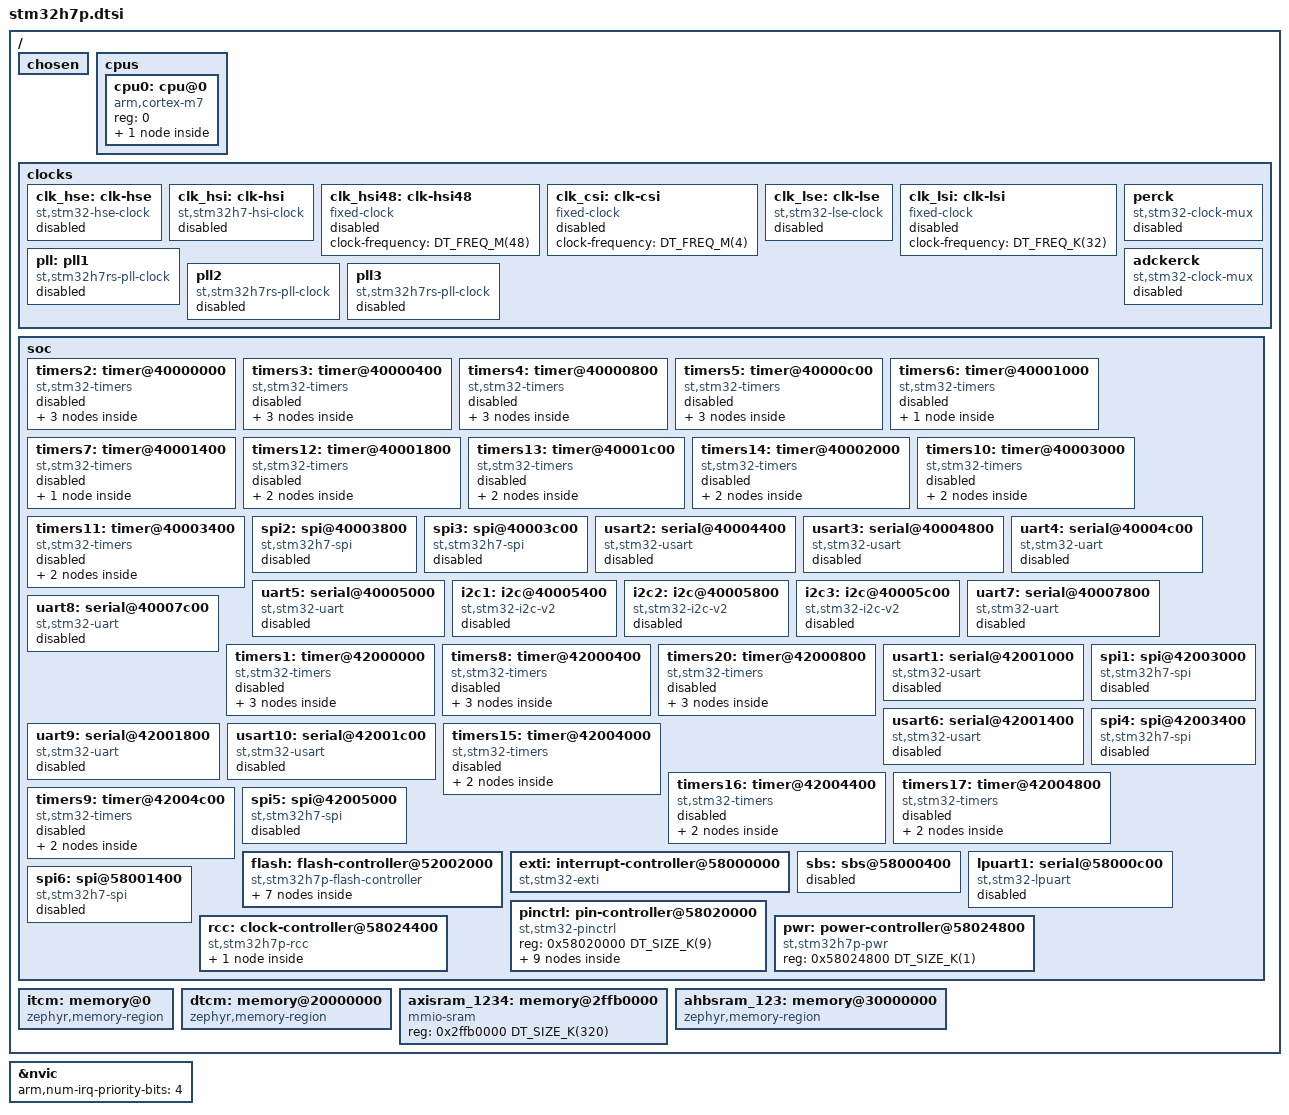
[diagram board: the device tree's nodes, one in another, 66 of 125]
/*
 * SPDX-FileCopyrightText: Copyright (c) 2026 STMicroelectronics
 *
 * SPDX-License-Identifier: Apache-2.0
 */

#include <arm/armv7-m.dtsi>
#include <zephyr/dt-bindings/adc/adc.h>
#include <zephyr/dt-bindings/clock/stm32h7p_clock.h>
#include <zephyr/dt-bindings/gpio/gpio.h>
#include <zephyr/dt-bindings/i2c/i2c.h>
#include <zephyr/dt-bindings/reset/stm32h7p_reset.h>
#include <zephyr/dt-bindings/dma/stm32_dma.h>
#include <zephyr/dt-bindings/power/stm32_pwr.h>
#include <zephyr/dt-bindings/pwm/pwm.h>
#include <zephyr/dt-bindings/sensor/qdec_stm32.h>
#include <freq.h>
#include <mem.h>

/ {
	chosen {
		zephyr,flash-controller = &flash;
		zephyr,flash = &flash0;
		zephyr,sram = &axisram_1234;
	};

	cpus {
		#address-cells = <1>;
		#size-cells = <0>;

		cpu0: cpu@0 {
			compatible = "arm,cortex-m7";
			reg = <0>;
			device_type = "cpu";
			#address-cells = <1>;
			#size-cells = <1>;

			mpu: mpu@e000ed90 {
				compatible = "arm,armv7m-mpu";
				reg = <0xe000ed90 0x40>;
			};
		};
	};

	clocks {
		clk_hse: clk-hse {
			compatible = "st,stm32-hse-clock";
			#clock-cells = <0>;
			status = "disabled";
		};

		clk_hsi: clk-hsi {
			compatible = "st,stm32h7-hsi-clock";
			#clock-cells = <0>;
			hsi-div = <1>;
			clock-frequency = <DT_FREQ_M(64)>;
			status = "disabled";
		};

		clk_hsi48: clk-hsi48 {
			compatible = "fixed-clock";
			#clock-cells = <0>;
			clock-frequency = <DT_FREQ_M(48)>;
			status = "disabled";
		};

		clk_csi: clk-csi {
			compatible = "fixed-clock";
			#clock-cells = <0>;
			clock-frequency = <DT_FREQ_M(4)>;
			status = "disabled";
		};

		clk_lse: clk-lse {
			compatible = "st,stm32-lse-clock";
			#clock-cells = <0>;
			clock-frequency = <32768>;
			driving-capability = <0>;
			status = "disabled";
		};

		clk_lsi: clk-lsi {
			compatible = "fixed-clock";
			#clock-cells = <0>;
			clock-frequency = <DT_FREQ_K(32)>;
			status = "disabled";
		};

		/* NOTE: PLL1 does not have R and T outputs */
		pll: pll1 {
			compatible = "st,stm32h7rs-pll-clock";
			#clock-cells = <0>;
			status = "disabled";
		};

		pll2: pll2 {
			compatible = "st,stm32h7rs-pll-clock";
			#clock-cells = <0>;
			status = "disabled";
		};

		/* NOTE: PLL3 does not have T output */
		pll3: pll3 {
			compatible = "st,stm32h7rs-pll-clock";
			#clock-cells = <0>;
			status = "disabled";
		};

		perck: perck {
			compatible = "st,stm32-clock-mux";
			#clock-cells = <0>;
			status = "disabled";
		};

		adckerck: adckerck {
			compatible = "st,stm32-clock-mux";
			#clock-cells = <0>;
			status = "disabled";
		};
	};

	soc {
		/* APB1 peripherals */
		timers2: timer@40000000 {
			compatible = "st,stm32-timers";
			reg = <0x40000000 DT_SIZE_K(1)>;
			clocks = <&rcc STM32_CLOCK(APB1, 0)>,
				 <&rcc STM32_SRC_TIMCK NO_SEL>;
			resets = <&rctl STM32_RESET(APB1L, 0)>;
			interrupts = <51 0>;
			interrupt-names = "global";
			st,prescaler = <0>;
			status = "disabled";

			counter {
				compatible = "st,stm32-counter";
				status = "disabled";
			};

			pwm {
				compatible = "st,stm32-pwm";
				#pwm-cells = <3>;
				status = "disabled";
			};

			qdec {
				compatible = "st,stm32-qdec";
				st,input-filter-level = <NO_FILTER>;
				status = "disabled";
			};
		};

		timers3: timer@40000400 {
			compatible = "st,stm32-timers";
			reg = <0x40000400 DT_SIZE_K(1)>;
			clocks = <&rcc STM32_CLOCK(APB1, 1)>,
				 <&rcc STM32_SRC_TIMCK NO_SEL>;
			resets = <&rctl STM32_RESET(APB1L, 1)>;
			interrupts = <52 0>;
			interrupt-names = "global";
			st,prescaler = <0>;
			status = "disabled";

			counter {
				compatible = "st,stm32-counter";
				status = "disabled";
			};

			pwm {
				compatible = "st,stm32-pwm";
				#pwm-cells = <3>;
				status = "disabled";
			};

			qdec {
				compatible = "st,stm32-qdec";
				st,input-filter-level = <NO_FILTER>;
				status = "disabled";
			};
		};

		timers4: timer@40000800 {
			compatible = "st,stm32-timers";
			reg = <0x40000800 DT_SIZE_K(1)>;
			clocks = <&rcc STM32_CLOCK(APB1, 2)>,
				 <&rcc STM32_SRC_TIMCK NO_SEL>;
			resets = <&rctl STM32_RESET(APB1L, 2)>;
			interrupts = <53 0>;
			interrupt-names = "global";
			st,prescaler = <0>;
			status = "disabled";

			counter {
				compatible = "st,stm32-counter";
				status = "disabled";
			};

			pwm {
				compatible = "st,stm32-pwm";
				#pwm-cells = <3>;
				status = "disabled";
			};

			qdec {
				compatible = "st,stm32-qdec";
				st,input-filter-level = <NO_FILTER>;
				status = "disabled";
			};
		};

		timers5: timer@40000c00 {
			compatible = "st,stm32-timers";
			reg = <0x40000c00 DT_SIZE_K(1)>;
			clocks = <&rcc STM32_CLOCK(APB1, 3)>,
				 <&rcc STM32_SRC_TIMCK NO_SEL>;
			resets = <&rctl STM32_RESET(APB1L, 3)>;
			interrupts = <54 0>;
			interrupt-names = "global";
			st,prescaler = <0>;
			status = "disabled";

			counter {
				compatible = "st,stm32-counter";
				status = "disabled";
			};

			pwm {
				compatible = "st,stm32-pwm";
				#pwm-cells = <3>;
				status = "disabled";
			};

			qdec {
				compatible = "st,stm32-qdec";
				st,input-filter-level = <NO_FILTER>;
				status = "disabled";
			};
		};

		timers6: timer@40001000 {
			compatible = "st,stm32-timers";
			reg = <0x40001000 DT_SIZE_K(1)>;
			clocks = <&rcc STM32_CLOCK(APB1, 4)>,
				 <&rcc STM32_SRC_TIMCK NO_SEL>;
			resets = <&rctl STM32_RESET(APB1L, 4)>;
			interrupts = <55 0>;
			interrupt-names = "global";
			st,prescaler = <0>;
			status = "disabled";

			counter {
				compatible = "st,stm32-counter";
				status = "disabled";
			};
		};

		timers7: timer@40001400 {
			compatible = "st,stm32-timers";
			reg = <0x40001400 DT_SIZE_K(1)>;
			clocks = <&rcc STM32_CLOCK(APB1, 5)>,
				 <&rcc STM32_SRC_TIMCK NO_SEL>;
			resets = <&rctl STM32_RESET(APB1L, 5)>;
			interrupts = <56 0>;
			interrupt-names = "global";
			st,prescaler = <0>;
			status = "disabled";

			counter {
				compatible = "st,stm32-counter";
				status = "disabled";
			};
		};

		timers12: timer@40001800 {
			compatible = "st,stm32-timers";
			reg = <0x40001800 DT_SIZE_K(1)>;
			clocks = <&rcc STM32_CLOCK(APB1, 6)>,
				 <&rcc STM32_SRC_TIMCK NO_SEL>;
			resets = <&rctl STM32_RESET(APB1L, 6)>;
			interrupts = <113 0>;
			interrupt-names = "global";
			st,prescaler = <0>;
			status = "disabled";

			counter {
				compatible = "st,stm32-counter";
				status = "disabled";
			};

			pwm {
				compatible = "st,stm32-pwm";
				#pwm-cells = <3>;
				status = "disabled";
			};
		};

		timers13: timer@40001c00 {
			compatible = "st,stm32-timers";
			reg = <0x40001c00 DT_SIZE_K(1)>;
			clocks = <&rcc STM32_CLOCK(APB1, 7)>,
				 <&rcc STM32_SRC_TIMCK NO_SEL>;
			resets = <&rctl STM32_RESET(APB1L, 7)>;
			interrupts = <114 0>;
			interrupt-names = "global";
			st,prescaler = <0>;
			status = "disabled";

			counter {
				compatible = "st,stm32-counter";
				status = "disabled";
			};

			pwm {
				compatible = "st,stm32-pwm";
				#pwm-cells = <3>;
				status = "disabled";
			};
		};

		timers14: timer@40002000 {
			compatible = "st,stm32-timers";
			reg = <0x40002000 DT_SIZE_K(1)>;
			clocks = <&rcc STM32_CLOCK(APB1, 8)>,
				 <&rcc STM32_SRC_TIMCK NO_SEL>;
			resets = <&rctl STM32_RESET(APB1L, 8)>;
			interrupts = <115 0>;
			interrupt-names = "global";
			st,prescaler = <0>;
			status = "disabled";

			counter {
				compatible = "st,stm32-counter";
				status = "disabled";
			};

			pwm {
				compatible = "st,stm32-pwm";
				#pwm-cells = <3>;
				status = "disabled";
			};
		};

		timers10: timer@40003000 {
			compatible = "st,stm32-timers";
			reg = <0x40003000 DT_SIZE_K(1)>;
			clocks = <&rcc STM32_CLOCK(APB1, 12)>,
				 <&rcc STM32_SRC_TIMCK NO_SEL>;
			resets = <&rctl STM32_RESET(APB1L, 12)>;
			interrupts = <99 0>;
			interrupt-names = "global";
			st,prescaler = <0>;
			status = "disabled";

			pwm {
				compatible = "st,stm32-pwm";
				#pwm-cells = <3>;
				status = "disabled";
			};

			counter {
				compatible = "st,stm32-counter";
				status = "disabled";
			};
		};

		timers11: timer@40003400 {
			compatible = "st,stm32-timers";
			reg = <0x40003400 DT_SIZE_K(1)>;
			clocks = <&rcc STM32_CLOCK(APB1, 13)>,
				 <&rcc STM32_SRC_TIMCK NO_SEL>;
			resets = <&rctl STM32_RESET(APB1L, 13)>;
			interrupts = <100 0>;
			interrupt-names = "global";
			st,prescaler = <0>;
			status = "disabled";

			pwm {
				compatible = "st,stm32-pwm";
				#pwm-cells = <3>;
				status = "disabled";
			};

			counter {
				compatible = "st,stm32-counter";
				status = "disabled";
			};
		};

		spi2: spi@40003800 {
			/* NOTE: this instance supports I2S mode */
			compatible = "st,stm32h7-spi", "st,stm32-spi-fifo", "st,stm32-spi";
			reg = <0x40003800 DT_SIZE_K(1)>;
			#address-cells = <1>;
			#size-cells = <0>;
			clocks = <&rcc STM32_CLOCK(APB1, 14)>;
			interrupts = <59 0>;
			fifo-size = <16>;
			fifo-max-transfer-size = <65535>;
			st,spi-data-width = "full-4-to-32-bit";

			status = "disabled";
		};

		spi3: spi@40003c00 {
			/* NOTE: this instance supports I2S mode */
			compatible = "st,stm32h7-spi", "st,stm32-spi-fifo", "st,stm32-spi";
			reg = <0x40003c00 DT_SIZE_K(1)>;
			#address-cells = <1>;
			#size-cells = <0>;
			clocks = <&rcc STM32_CLOCK(APB1, 15)>;
			interrupts = <60 0>;
			fifo-size = <16>;
			fifo-max-transfer-size = <65535>;
			st,spi-data-width = "full-4-to-32-bit";

			status = "disabled";
		};

		usart2: serial@40004400 {
			compatible = "st,stm32-usart", "st,stm32-uart";
			reg = <0x40004400 DT_SIZE_K(1)>;
			clocks = <&rcc STM32_CLOCK(APB1, 17)>;
			resets = <&rctl STM32_RESET(APB1L, 17)>;
			interrupts = <83 0>;

			status = "disabled";
		};

		usart3: serial@40004800 {
			compatible = "st,stm32-usart", "st,stm32-uart";
			reg = <0x40004800 DT_SIZE_K(1)>;
			clocks = <&rcc STM32_CLOCK(APB1, 18)>;
			resets = <&rctl STM32_RESET(APB1L, 18)>;
			interrupts = <84 0>;
			status = "disabled";
		};

		uart4: serial@40004c00 {
			compatible = "st,stm32-uart";
			reg = <0x40004c00 DT_SIZE_K(1)>;
			clocks = <&rcc STM32_CLOCK(APB1, 19)>;
			resets = <&rctl STM32_RESET(APB1L, 19)>;
			interrupts = <85 0>;
			status = "disabled";
		};

		uart5: serial@40005000 {
			compatible = "st,stm32-uart";
			reg = <0x40005000 DT_SIZE_K(1)>;
			clocks = <&rcc STM32_CLOCK(APB1, 20)>;
			resets = <&rctl STM32_RESET(APB1L, 20)>;
			interrupts = <86 0>;
			status = "disabled";
		};

		i2c1: i2c@40005400 {
			compatible = "st,stm32-i2c-v2";
			reg = <0x40005400 DT_SIZE_K(1)>;
			#address-cells = <1>;
			#size-cells = <0>;
			clocks = <&rcc STM32_CLOCK(APB1, 21)>;
			interrupts = <76 0>, <77 0>;
			interrupt-names = "event", "error";
			status = "disabled";
		};

		i2c2: i2c@40005800 {
			compatible = "st,stm32-i2c-v2";
			reg = <0x40005800 DT_SIZE_K(1)>;
			#address-cells = <1>;
			#size-cells = <0>;
			clocks = <&rcc STM32_CLOCK(APB1, 22)>;
			interrupts = <78 0>, <79 0>;
			interrupt-names = "event", "error";
			status = "disabled";
		};

		i2c3: i2c@40005c00 {
			compatible = "st,stm32-i2c-v2";
			reg = <0x40005c00 DT_SIZE_K(1)>;
			#address-cells = <1>;
			#size-cells = <0>;
			clocks = <&rcc STM32_CLOCK(APB1, 23)>;
			interrupts = <80 0>, <81 0>;
			interrupt-names = "event", "error";
			status = "disabled";
		};

		uart7: serial@40007800 {
			compatible = "st,stm32-uart";
			reg = <0x40007800 DT_SIZE_K(1)>;
			clocks = <&rcc STM32_CLOCK(APB1, 30)>;
			resets = <&rctl STM32_RESET(APB1L, 30)>;
			interrupts = <87 0>;
			status = "disabled";
		};

		uart8: serial@40007c00 {
			compatible = "st,stm32-uart";
			reg = <0x40007c00 DT_SIZE_K(1)>;
			clocks = <&rcc STM32_CLOCK(APB1, 31)>;
			resets = <&rctl STM32_RESET(APB1L, 31)>;
			interrupts = <88 0>;
			status = "disabled";
		};

		/* AHB1 peripherals: HSP/GPDMA/OTGFS/ADF (not supported yet) */
		/* APB2 peripherals */
		timers1: timer@42000000 {
			compatible = "st,stm32-timers";
			reg = <0x42000000 DT_SIZE_K(1)>;
			clocks = <&rcc STM32_CLOCK(APB2, 0)>,
				 <&rcc STM32_SRC_TIMCK NO_SEL>;
			resets = <&rctl STM32_RESET(APB2, 0)>;
			interrupts = <47 0>, <48 0>, <49 0>, <50 0>;
			interrupt-names = "brk", "up", "trgcom", "cc";
			st,prescaler = <0>;
			status = "disabled";

			counter {
				compatible = "st,stm32-counter";
				status = "disabled";
			};

			pwm {
				compatible = "st,stm32-pwm";
				#pwm-cells = <3>;
				status = "disabled";
			};

			qdec {
				compatible = "st,stm32-qdec";
				st,input-filter-level = <NO_FILTER>;
				status = "disabled";
			};
		};

		timers8: timer@42000400 {
			compatible = "st,stm32-timers";
			reg = <0x42000400 DT_SIZE_K(1)>;
			clocks = <&rcc STM32_CLOCK(APB2, 1)>,
				 <&rcc STM32_SRC_TIMCK NO_SEL>;
			resets = <&rctl STM32_RESET(APB2, 1)>;
			interrupts = <72 0>, <73 0>, <74 0>, <75 0>;
			interrupt-names = "brk", "up", "trgcom", "cc";
			st,prescaler = <0>;
			status = "disabled";

			counter {
				compatible = "st,stm32-counter";
				status = "disabled";
			};

			pwm {
				compatible = "st,stm32-pwm";
				#pwm-cells = <3>;
				status = "disabled";
			};

			qdec {
				compatible = "st,stm32-qdec";
				st,input-filter-level = <NO_FILTER>;
				status = "disabled";
			};
		};

		timers20: timer@42000800 {
			compatible = "st,stm32-timers";
			reg = <0x42000800 DT_SIZE_K(1)>;
			clocks = <&rcc STM32_CLOCK(APB2, 2)>,
				 <&rcc STM32_SRC_TIMCK NO_SEL>;
			resets = <&rctl STM32_RESET(APB2, 2)>;
			interrupts = <95 0>, <96 0>, <97 0>, <98 0>;
			interrupt-names = "brk", "up", "trgcom", "cc";
			st,prescaler = <0>;
			status = "disabled";

			counter {
				compatible = "st,stm32-counter";
				status = "disabled";
			};

			pwm {
				compatible = "st,stm32-pwm";
				#pwm-cells = <3>;
				status = "disabled";
			};

			qdec {
				compatible = "st,stm32-qdec";
				st,input-filter-level = <NO_FILTER>;
				status = "disabled";
			};
		};

		usart1: serial@42001000 {
			compatible = "st,stm32-usart", "st,stm32-uart";
			reg = <0x42001000 DT_SIZE_K(1)>;
			clocks = <&rcc STM32_CLOCK(APB2, 4)>;
			resets = <&rctl STM32_RESET(APB2, 4)>;
			interrupts = <82 0>;
			status = "disabled";
		};

		usart6: serial@42001400 {
			compatible = "st,stm32-usart", "st,stm32-uart";
			reg = <0x42001400 DT_SIZE_K(1)>;
			clocks = <&rcc STM32_CLOCK(APB2, 5)>;
			resets = <&rctl STM32_RESET(APB2, 5)>;
			interrupts = <130 0>;
			status = "disabled";
		};

		uart9: serial@42001800 {
			compatible = "st,stm32-uart";
			reg = <0x42001800 DT_SIZE_K(1)>;
			clocks = <&rcc STM32_CLOCK(APB2, 6)>;
			resets = <&rctl STM32_RESET(APB2, 6)>;
			interrupts = <124 0>;
			status = "disabled";
		};

		usart10: serial@42001c00 {
			compatible = "st,stm32-usart", "st,stm32-uart";
			reg = <0x42001c00 DT_SIZE_K(1)>;
			clocks = <&rcc STM32_CLOCK(APB2, 7)>;
			resets = <&rctl STM32_RESET(APB2, 7)>;
			interrupts = <125 0>;
			status = "disabled";
		};

		spi1: spi@42003000 {
			/* NOTE: this instance supports I2S mode */
			compatible = "st,stm32h7-spi", "st,stm32-spi-fifo", "st,stm32-spi";
			reg = <0x42003000 DT_SIZE_K(1)>;
			#address-cells = <1>;
			#size-cells = <0>;
			clocks = <&rcc STM32_CLOCK(APB2, 12)>;
			interrupts = <58 0>;
			fifo-size = <16>;
			fifo-max-transfer-size = <65535>;
			st,spi-data-width = "full-4-to-32-bit";

			status = "disabled";
		};

		spi4: spi@42003400 {
			compatible = "st,stm32h7-spi", "st,stm32-spi-fifo", "st,stm32-spi";
			reg = <0x42003400 DT_SIZE_K(1)>;
			#address-cells = <1>;
			#size-cells = <0>;
			clocks = <&rcc STM32_CLOCK(APB2, 13)>;
			interrupts = <61 0>;
			fifo-size = <8>;
			fifo-max-transfer-size = <65535>;
			st,spi-data-width = "full-4-to-16-bit";

			status = "disabled";
		};

		timers15: timer@42004000 {
			compatible = "st,stm32-timers";
			reg = <0x42004000 DT_SIZE_K(1)>;
			clocks = <&rcc STM32_CLOCK(APB2, 16)>,
				 <&rcc STM32_SRC_TIMCK NO_SEL>;
			resets = <&rctl STM32_RESET(APB2, 16)>;
			interrupts = <116 0>;
			interrupt-names = "global";
			st,prescaler = <0>;
			status = "disabled";

			counter {
				compatible = "st,stm32-counter";
				status = "disabled";
			};

			pwm {
				compatible = "st,stm32-pwm";
				#pwm-cells = <3>;
				status = "disabled";
			};
		};

		timers16: timer@42004400 {
			compatible = "st,stm32-timers";
			reg = <0x42004400 DT_SIZE_K(1)>;
			clocks = <&rcc STM32_CLOCK(APB2, 17)>,
				 <&rcc STM32_SRC_TIMCK NO_SEL>;
			resets = <&rctl STM32_RESET(APB2, 17)>;
			interrupts = <117 0>;
			interrupt-names = "global";
			st,prescaler = <0>;
			status = "disabled";

			counter {
				compatible = "st,stm32-counter";
				status = "disabled";
			};

			pwm {
				compatible = "st,stm32-pwm";
				#pwm-cells = <3>;
				status = "disabled";
			};
		};

		timers17: timer@42004800 {
			compatible = "st,stm32-timers";
			reg = <0x42004800 DT_SIZE_K(1)>;
			clocks = <&rcc STM32_CLOCK(APB2, 18)>,
				 <&rcc STM32_SRC_TIMCK NO_SEL>;
			resets = <&rctl STM32_RESET(APB2, 18)>;
			interrupts = <118 0>;
			interrupt-names = "global";
			st,prescaler = <0>;
			status = "disabled";

			counter {
				compatible = "st,stm32-counter";
				status = "disabled";
			};

			pwm {
				compatible = "st,stm32-pwm";
				#pwm-cells = <3>;
				status = "disabled";
			};
		};

		timers9: timer@42004c00 {
			compatible = "st,stm32-timers";
			reg = <0x42004c00 DT_SIZE_K(1)>;
			clocks = <&rcc STM32_CLOCK(APB2, 19)>,
				 <&rcc STM32_SRC_TIMCK NO_SEL>;
			resets = <&rctl STM32_RESET(APB2, 19)>;
			interrupts = <57 0>;
			interrupt-names = "global";
			st,prescaler = <0>;
			status = "disabled";

			counter {
				compatible = "st,stm32-counter";
				status = "disabled";
			};

			pwm {
				compatible = "st,stm32-pwm";
				#pwm-cells = <3>;
				status = "disabled";
			};
		};

		spi5: spi@42005000 {
			compatible = "st,stm32h7-spi", "st,stm32-spi-fifo", "st,stm32-spi";
			reg = <0x42005000 DT_SIZE_K(1)>;
			#address-cells = <1>;
			#size-cells = <0>;
			clocks = <&rcc STM32_CLOCK(APB2, 20)>;
			interrupts = <62 0>;
			fifo-size = <8>;
			fifo-max-transfer-size = <65535>;
			st,spi-data-width = "full-4-to-16-bit";

			status = "disabled";
		};

		/* AHB2 peripherals: CORDIC/FMAC (not supported yet) */
		/* AHB3 peripherals: RNG/HASH (not supported yet) */
		/* AHB5 peripherals */
		flash: flash-controller@52002000 {
			compatible = "st,stm32h7p-flash-controller", "st,stm32-flash-controller";
			reg = <0x52002000 DT_SIZE_K(4)>;
			ranges;
			#address-cells = <1>;
			#size-cells = <1>;
			interrupts = <8 0>;

			flash0: flash@8000000 {
				compatible = "st,stm32-nv-flash", "soc-nv-flash";
				#address-cells = <1>;
				#size-cells = <1>;
				write-block-size = <16>;
				erase-block-size = <8192>;

				/* max erase time for sector (8K) */
				max-erase-time = <3>;
			};

			st_nvm_user_otp: flash@8fff000 {
				compatible = "st,stm32-nvm-otp";
				reg = <0x08fff000 DT_SIZE_K(1)>;
				status = "disabled";
			};

			/* "Read-only area" */
			flash@8fff800 {
				compatible = "st,stm32-nvm-otp";
				reg = <0x08fff800 512>;

				nvmem-layout {
					compatible = "fixed-layout";
					#address-cells = <1>;
					#size-cells = <1>;

					vrefint_otp: vrefint@10 {
						reg = <0x10 0x2>;
						#nvmem-cell-cells = <0>;
						read-only;
					};

					ts_cal1_otp: ts-cal1@14 {
						reg = <0x14 0x2>;
						#nvmem-cell-cells = <0>;
						read-only;
					};

					ts_cal2_otp: ts-cal2@18 {
						reg = <0x18 0x2>;
						#nvmem-cell-cells = <0>;
						read-only;
					};
				};
			};
		};

		/* APB4 peripherals */
		exti: interrupt-controller@58000000 {
			compatible = "st,stm32-exti";
			reg = <0x58000000 DT_SIZE_K(1)>;
			interrupt-controller;
			#interrupt-cells = <1>;
			#address-cells = <0>;
			clocks = <&rcc STM32_CLOCK(APB4, 1)>; /* SBSEN */
			interrupts = <16 0>, <17 0>, <18 0>, <19 0>,
				     <20 0>, <21 0>, <22 0>, <23 0>,
				     <24 0>, <25 0>, <26 0>, <27 0>,
				     <28 0>, <29 0>, <30 0>, <31 0>;
			interrupt-names = "line0", "line1", "line2", "line3",
					  "line4", "line5", "line6", "line7",
					  "line8", "line9", "line10", "line11",
					  "line12", "line13", "line14", "line15";
			line-ranges = <0 1>, <1 1>, <2 1>, <3 1>,
				      <4 1>, <5 1>, <6 1>, <7 1>,
				      <8 1>, <9 1>, <10 1>, <11 1>,
				      <12 1>, <13 1>, <14 1>, <15 1>;
			num-lines = <78>;
		};

		sbs: sbs@58000400 {
			reg = <0x58000400 DT_SIZE_K(1)>;
			clocks = <&rcc STM32_CLOCK(APB4, 1)>;
			resets = <&rctl STM32_RESET(APB4, 1)>;
			status = "disabled";
		};

		lpuart1: serial@58000c00 {
			compatible = "st,stm32-lpuart", "st,stm32-uart";
			reg = <0x58000c00 DT_SIZE_K(1)>;
			clocks = <&rcc STM32_CLOCK(APB4, 3)>;
			resets = <&rctl STM32_RESET(APB4, 3)>;
			interrupts = <131 0>;
			status = "disabled";
		};

		spi6: spi@58001400 {
			compatible = "st,stm32h7-spi", "st,stm32-spi-fifo", "st,stm32-spi";
			reg = <0x58001400 DT_SIZE_K(1)>;
			#address-cells = <1>;
			#size-cells = <0>;
			clocks = <&rcc STM32_CLOCK(APB4, 5)>;
			interrupts = <63 0>;
			fifo-size = <8>;
			fifo-max-transfer-size = <65535>;
			st,spi-data-width = "full-4-to-16-bit";

			status = "disabled";
		};

		/* AHB4 peripherals */
		pinctrl: pin-controller@58020000 {
			compatible = "st,stm32-pinctrl";
			reg = <0x58020000 DT_SIZE_K(9)>;
			ranges;
			#address-cells = <1>;
			#size-cells = <1>;

			gpioa: gpio@58020000 {
				compatible = "st,stm32-gpio";
				reg = <0x58020000 DT_SIZE_K(1)>;
				clocks = <&rcc STM32_CLOCK(AHB4, 0)>;
				#gpio-cells = <2>;
				gpio-controller;
			};

			gpiob: gpio@58020400 {
				compatible = "st,stm32-gpio";
				reg = <0x58020400 DT_SIZE_K(1)>;
				clocks = <&rcc STM32_CLOCK(AHB4, 1)>;
				#gpio-cells = <2>;
				gpio-controller;
			};

			gpioc: gpio@58020800 {
				compatible = "st,stm32-gpio";
				reg = <0x58020800 DT_SIZE_K(1)>;
				clocks = <&rcc STM32_CLOCK(AHB4, 2)>;
				#gpio-cells = <2>;
				gpio-controller;
			};

			gpiod: gpio@58020c00 {
				compatible = "st,stm32-gpio";
				reg = <0x58020c00 DT_SIZE_K(1)>;
				clocks = <&rcc STM32_CLOCK(AHB4, 3)>;
				#gpio-cells = <2>;
				gpio-controller;
			};

			gpioe: gpio@58021000 {
				compatible = "st,stm32-gpio";
				reg = <0x58021000 DT_SIZE_K(1)>;
				clocks = <&rcc STM32_CLOCK(AHB4, 4)>;
				#gpio-cells = <2>;
				gpio-controller;
			};

			gpiof: gpio@58021400 {
				compatible = "st,stm32-gpio";
				reg = <0x58021400 DT_SIZE_K(1)>;
				clocks = <&rcc STM32_CLOCK(AHB4, 5)>;
				#gpio-cells = <2>;
				gpio-controller;
			};

			gpiog: gpio@58021800 {
				compatible = "st,stm32-gpio";
				reg = <0x58021800 DT_SIZE_K(1)>;
				clocks = <&rcc STM32_CLOCK(AHB4, 6)>;
				#gpio-cells = <2>;
				gpio-controller;
			};

			gpioh: gpio@58021c00 {
				compatible = "st,stm32-gpio";
				reg = <0x58021c00 DT_SIZE_K(1)>;
				clocks = <&rcc STM32_CLOCK(AHB4, 7)>;
				#gpio-cells = <2>;
				gpio-controller;
			};

			gpioi: gpio@58022000 {
				compatible = "st,stm32-gpio";
				reg = <0x58022000 DT_SIZE_K(1)>;
				clocks = <&rcc STM32_CLOCK(AHB4, 8)>;
				#gpio-cells = <2>;
				gpio-controller;
			};
		};

		rcc: clock-controller@58024400 {
			compatible = "st,stm32h7p-rcc";
			reg = <0x58024400 DT_SIZE_K(1)>;
			#clock-cells = <2>;

			st,clock-sources = <&perck>, <&adckerck>;
			st,clock-source-identifiers = <STM32_SRC_CKPER>, <STM32_SRC_ADCKERCK>;

			rctl: reset-controller {
				compatible = "st,stm32-rcc-rctl";
				#reset-cells = <1>;
			};
		};

		pwr: power-controller@58024800 {
			compatible = "st,stm32h7p-pwr", "st,stm32-pwr";
			reg = <0x58024800 DT_SIZE_K(1)>;
		};

		/* Debug bus: DBGMCU (not supported yet) */
	};

	itcm: memory@0 {
		compatible = "zephyr,memory-region", "arm,itcm";
		reg = <0x00000000 DT_SIZE_K(192)>;
		zephyr,memory-region = "ITCM";
	};

	dtcm: memory@20000000 {
		compatible = "zephyr,memory-region", "arm,dtcm";
		reg = <0x20000000 DT_SIZE_K(128)>;
		zephyr,memory-region = "DTCM";
	};

	axisram_1234: memory@2ffb0000 {
		/*
		 * 128 KiB AXISRAM1 + 3x64 KiB AXISRAM2/3/4
		 *
		 * AXISRAM1 is erased by hardware after power-on reset
		 * and can be configured to be erased by tamper events.
		 */
		compatible = "mmio-sram";
		reg = <0x2ffb0000 DT_SIZE_K(320)>;
	};

	ahbsram_123: memory@30000000 {
		/*
		 * 2x16 KiB AHBSRAM1/2 + 64 KiB AHBSRAM3
		 *
		 * AHBSRAM3 is dedicated to HSP when enabled.
		 *
		 * WARNING: these RAMs can be clock-gated by RCC.
		 * (but they are enabled after reset)
		 */
		compatible = "zephyr,memory-region", "mmio-sram";
		reg = <0x30000000 DT_SIZE_K(96)>;
		zephyr,memory-region = "AHBSRAM";
	};
};

&nvic {
	arm,num-irq-priority-bits = <4>;
};
